# WKUP_GTC0_GTC_CFG1 register map
Vendor: Texas Instruments
Peripheral module from a debugger description file (folder am62P).
Registers are 32-bit, read-only, reset 0x0 unless marked. A register's access mark holds for its fields unless they carry their own. Offsets are as the file gives them; lines under a group give offsets from that group; [hi:lo] are bit positions; {n}, {i} and the like mark numbered series; 'fields as' and 'values as' point back to an identical list; <NAME> marks a mode.

## WKUP_GTC0_GTC_CFG1
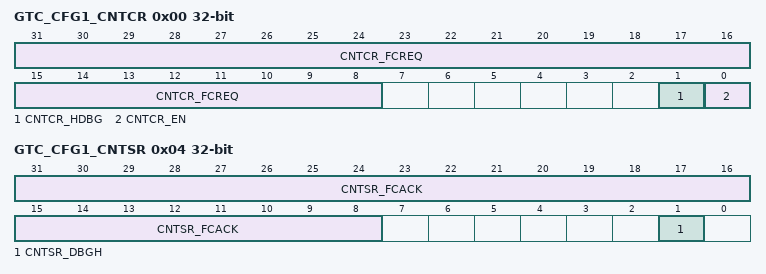
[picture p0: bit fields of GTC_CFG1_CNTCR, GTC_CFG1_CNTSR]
0x00 GTC_CFG1_CNTCR access per field
  [31:8] CNTCR_FCREQ ro — Frequency Change Request
  [1] CNTCR_HDBG rw — Halt on Debug
  [0] CNTCR_EN rw — Enable System Counter
0x04 GTC_CFG1_CNTSR
  [31:8] CNTSR_FCACK — Frequency Change Ackowledge
  [1] CNTSR_DBGH — Debug Halt
0x08 GTC_CFG1_CNTCV_LO
  [31:0] CNTCV_LO_COUNTVALUE — Indicates bits [31:0] of the System Counter value.
0x0C GTC_CFG1_CNTCV_HI
  [31:0] CNTCV_HI_COUNTVALUE — Indicates bits [63:32] of the System Counter value.
0x20 GTC_CFG1_CNTFID0 rw
  [31:0] CNTFID0_FREQVALUE — Indicates the base update frequency of the System Counter in Hz.
0x24 GTC_CFG1_CNTFID1
  [31:0] CNTFID1_FREQVALUE — Frequency table end indicator
